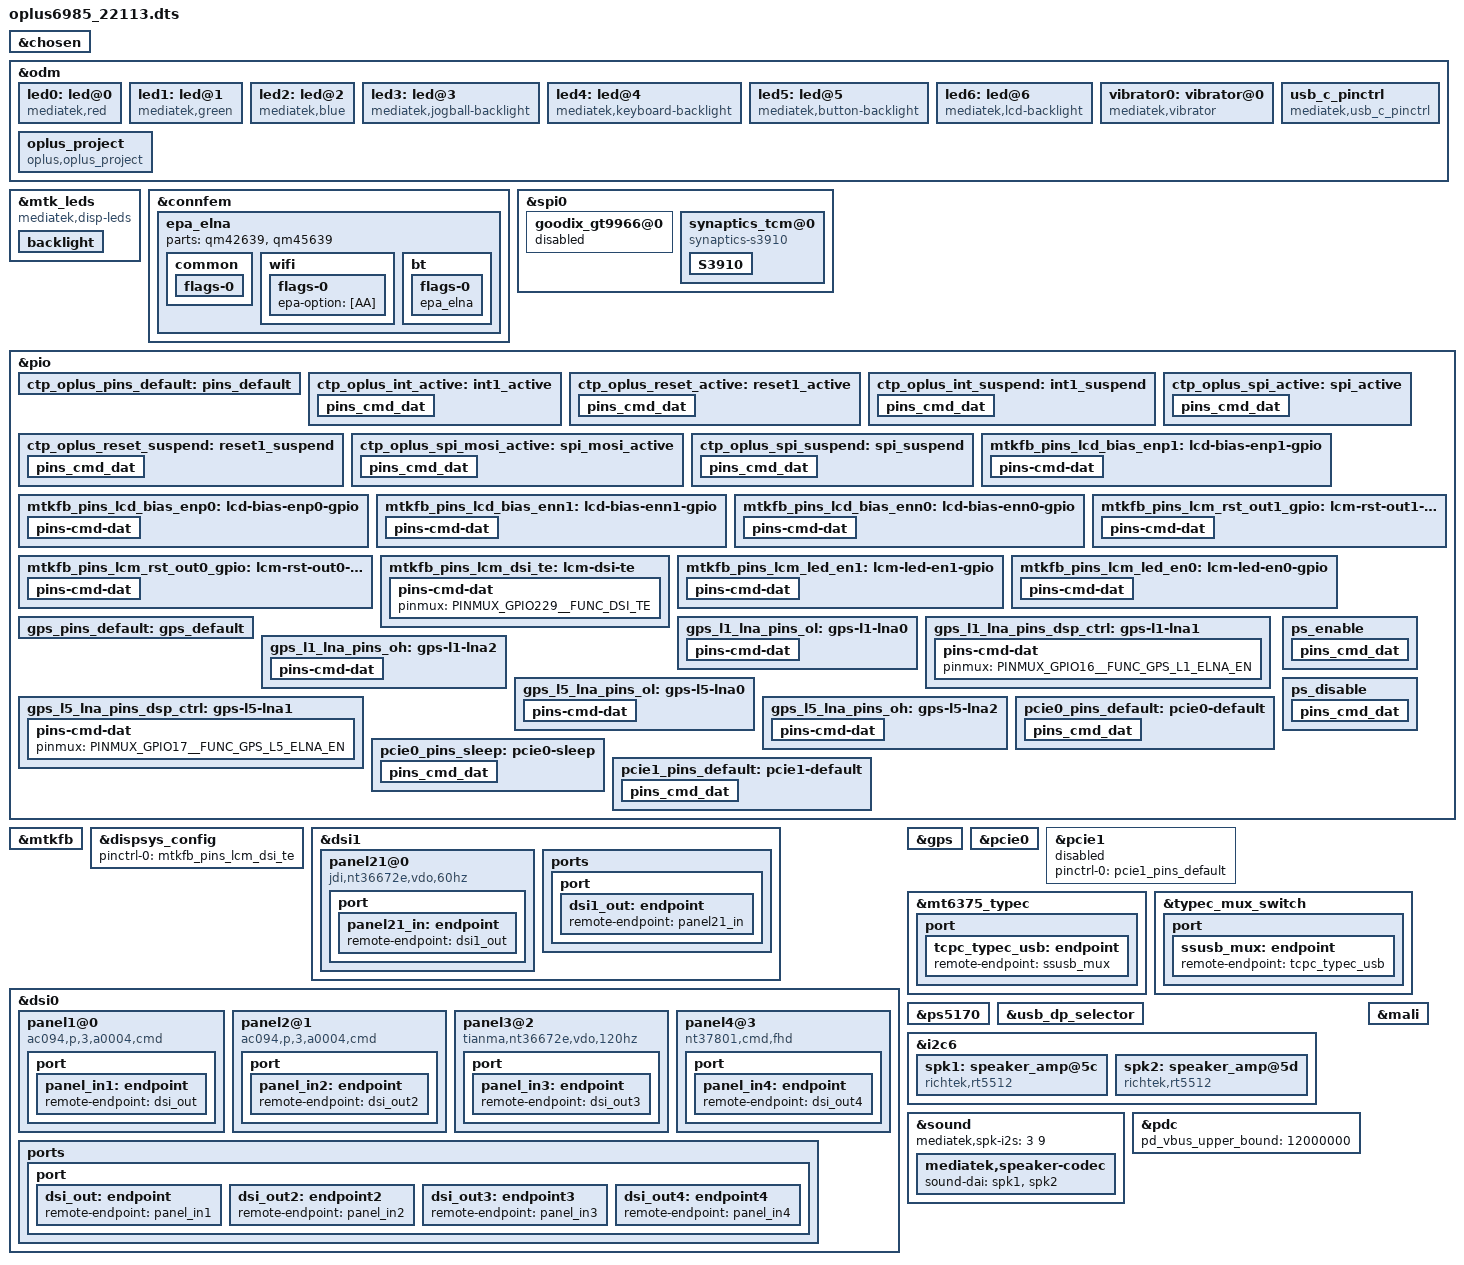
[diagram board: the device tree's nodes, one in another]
// SPDX-License-Identifier: (GPL-2.0 OR MIT)
/*
 * Copyright (C) 2022 MediaTek Inc.
 */
/dts-v1/;
/plugin/;
#include <dt-bindings/interrupt-controller/arm-gic.h>
#include <dt-bindings/interrupt-controller/irq.h>
#include <dt-bindings/pinctrl/mt6985-pinfunc.h>
#include <dt-bindings/phy/phy.h>

&chosen {
bootargs_ext = "console=tty0 root=/dev/ram vmalloc=400M \
loglevel=8 \
androidboot.hardware=mt6985 \
8250.nr_uarts=4 \
initcall_debug=1";
};

/** #ifdef OPLUS_DISPLAY_FEATURE **/
&odm {
	led0:led@0 {
		compatible = "mediatek,red";
		led_mode = <0>;
		data = <1>;
		pwm_config = <0 0 0 0 0>;
	};
	led1:led@1 {
		compatible = "mediatek,green";
		led_mode = <0>;
		data = <1>;
		pwm_config = <0 0 0 0 0>;
	};
	led2:led@2 {
		compatible = "mediatek,blue";
		led_mode = <0>;
		data = <1>;
		pwm_config = <0 0 0 0 0>;
	};
	led3:led@3 {
		compatible = "mediatek,jogball-backlight";
		led_mode = <0>;
		data = <1>;
		pwm_config = <0 0 0 0 0>;
	};
	led4:led@4 {
		compatible = "mediatek,keyboard-backlight";
		led_mode = <0>;
		data = <1>;
		pwm_config = <0 0 0 0 0>;
	};
	led5:led@5 {
		compatible = "mediatek,button-backlight";
		led_mode = <0>;
		data = <1>;
		pwm_config = <0 0 0 0 0>;
	};
	led6:led@6 {
		compatible = "mediatek,lcd-backlight";
		led_mode = <4>;
		data = <1>;
		pwm_config = <0 1 0 0 0>;
	};
	vibrator0:vibrator@0 {
		compatible = "mediatek,vibrator";
		vib_timer = <25>;
		vib_limit = <9>;
		vib_vol= <9>;
	};

	usb_c_pinctrl:usb_c_pinctrl {
		compatible = "mediatek,usb_c_pinctrl";
	};
};

&mtk_leds {
		compatible = "mediatek,disp-leds";
		backlight {
			label = "lcd-backlight";
			led_mode = <4>;
			min-brightness = <1>;
			max-brightness = <4095>;
			max-hw-brightness = <4095>;
			led-bits = <13>;
			trans-bits = <13>;
			default-state = "on";
	};
};
/** #endif OPLUS_DISPLAY_FEATURE **/

&connfem {
	/* Support Wifi & BT ePA/eLNA FEM on customer load */
	epa_elna {
		parts = <&qm42639 &qm45639>;

		common {
			flags-0 {
				rx-mode = [81];
				fe-ant-cnt = [82];
				fe-main-bt-share-lp2g = [81];
				fe-conn-spdt = [8F];
				fe-reserved = [82];
			};
		};

		wifi {
			flags-0 {
				epa-option = [AA];
				/* open-loop; */
			};
		};

		bt {
			flags-0 {
				/* choose one of: epa_elna/epa/elna/bypass */
				epa_elna;
			};
		};
	};
};

&spi0 {
	status = "okay";
	#address-cells = <1>;
	#size-cells = <0>;
 
	goodix_gt9966@0 {
		status = "disabled";
	}; 

	synaptics_tcm@0{
		compatible = "synaptics-s3910";
		reg = <0x0>;
		chip-name = "S3910";
		status = "okay";
		spi-max-frequency = <15000000>;
		/* Interrupt && Irq-gpio */
		interrupt-parent = <&pio>;
		interrupts = <8 0x2008>;

		/* Power Config */
		/* enable2v8_gpio  = <&pio 164 0x1>; */
		vdd_2v8-supply = <&mt6373_vtp>;
		vdd_2v8_volt = <3000000>;
		//vcc_1v8-supply  = <&mt6373_vmc>; 
		//vcc_1v8_volt = <1800000>;

		/* Other HW Resource */

		irq-gpio = <&pio 8 0x2008>;
		reset-gpio = <&pio 67 0x1>;
		//cs-gpio = <&pio 110 0x00>;

		pinctrl-names = "default",  "oplus_int_active",
		"oplus_reset_active", "oplus_int_suspend",
		"oplus_reset_suspend", "oplus_spi_active",
		"oplus_spi_suspend";
		pinctrl-0 = <&ctp_oplus_pins_default>;
		pinctrl-1 = <&ctp_oplus_int_active>;
		pinctrl-2 = <&ctp_oplus_reset_active>;
		pinctrl-3 = <&ctp_oplus_int_suspend>;
		pinctrl-4 = <&ctp_oplus_reset_suspend>;
		pinctrl-5 = <&ctp_oplus_spi_active>, <&ctp_oplus_spi_mosi_active>;
		pinctrl-6 = <&ctp_oplus_spi_suspend>;

		touchpanel,max-num-support = <10>;
		touchpanel,tx-rx-num = <16 36>;
		touchpanel,panel-coords = <12400 27720>;
		touchpanel,display-coords = <1240 2772>;
		touchpanel,touchmajor-limit = <128 216>;
		touchpanel,elimination-range = <20 200 200>;
		touchpanel,int-mode = <1>; /*0: interrupt and disable, 1:interrupt and not disable*/
		touchpanel,smooth-level = <0 1 2 4 7 9>;
		touchpanel,smooth-level-charging = <0 2 4 7 8 9>;
		touchpanel,sensitive-level = <0 70 55 40 25 10>;
		touchpanel,single-optimized-time = <8>;
		touchpanel,high-frame-rate-time = <60>;

		vid_len = <2>;
		panel_type = <7 7 7>; /*type:7 TIANMA*/
		platform_support_project = <21135 22113>;
		platform_support_project_dir = <21135 22113>;
		platform_support_project_commandline = "default_commandline", "oplus21135_tm_nt37705_fhd_dsi_cmd_lcm_drv", "oplus21121_boe_nt37701a_fhd_dsi_cmd_lcm_drv";

		prevention,curved_screen_V2;
		prevention,grip_disable_level = <6>;
		prevention,updelay_time_ms = <30>;
		prevention,makeup_cnt_weight = <4 1 2 2 2>;
		prevention,large_corner_range = <1380 3400>;
		prevention,large_corner_judge_condition = <500 300 1000 7 7>;
		prevention,trx_reject_condition = <8 7 7>;
		prevention,trx_strict_reject_condition = <8 6 6>;
		prevention,large_judge_time_ms = <500 50 30>;
		prevention,large_exit_condition = <8 8 2>;
		prevention,single_channel_width = <320 320>;
		prevention,normal_tap_condition = <10 350>;
		prevention,long_edge_condition = <179 90 120 80>;
		prevention,long_strict_edge_condition = <160 60>;
		prevention,long_fingerhold_condition = <70 6 4 4>;
		prevention,short_edge_condition = <179 90 120 80>;
		prevention,short_strict_edge_condition = <160 60>;
		prevention,large_strict_exit_condition = <6 6>;
		prevention,top_corner_config = <250 750 1000>;
		prevention,edge_swipe_config = <340 1130>;

		prevention,curved_screen_V4;
		prevention,long_eliminate_point_type = <2 12400 9240 240 27720 300 1>;
		prevention,long_fingerhold_condition2 = <700 2000 0 0>;
		prevention,top_corner_config2 =<3 80 600 1500 0>;
		prevention,hor_long_top_corner_config =<300 2000 0 0>;
		prevention,top_middle_config =<12400 1000 1000 0>;
		prevention,corner_eliminate_point_type =<0 1380 2270 1>;
		prevention,finger_hold_differ_size = <1 0 400 300>;
		prevention,finger_hold_max_rx_exit_distance = <5 350 2300>;
		prevention,max_rx_exit_distance = <1 5 150 350 2000>;
		prevention,dynamic_finger_hold_exit_distance = <1 350 2300 450>;

		/* SW Support Feature Control */
		black_gesture_support;
		sportify_aod_gesture_support;
		pressure_report_support;
		charger_pump_support;
		game_switch_support;
		glove_mode_support;
		smart_gesture_support;
		spi_port_support;
		fw_update_app_support;
		fingerprint_underscreen_support;
		freq_hop_simulate_support;
		report_flow_unlock_support;
		screenoff_fingerprint_info_support;
		irq_need_dev_resume_ok;
		enable_point_auto_change;
		kernel_grip_support;
		//grip_no_driver_support;
		health_monitor_support;
		black_gesture_indep_support;
		snr_read_support;
		exception_upload_support;
		/*
		 *Virtual Key Config:
		 *1:touchpanel,button-type: <virtualkey_type  supportted_button-map>
		 *virtualkey_type:
		 *Type 1: using board_properties
		 *Type 2: using same IC (button zone&& touch zone are seprate)
		 *Type 3: using diffrent IC (button zone&& touch zone are seprate)
		 *Type 4: No need of virtual key process
		 *supportted_button-map:select|menu|home|back
		 *
		 *2:touchpanel,button-map
		 *type (X1,Y1)(X2,Y2)(X3,Y3)(Width_X,Hight_Y)--Only when button-type is 0
		 */
		touchpanel,button-type = <4>;
		touchpanel.button-TRx = <0 0>;

		S3910 {
			switch_report_rate;
			report_rate_default = <60>;
			report_rate_game_value = <0x03>;
			fps_report_rate = <60 2 90 3 120 3>;//1:360Hz 2:125Hz 3:240Hz
			fwupdate_bootloader = <1>;
			normal_config_version = <2>;
			default_gesture_mask = <8191>;
		};
	};

};

/*add for nvwa TP*/
&pio {
	ctp_oplus_pins_default: pins_default {
	};
	ctp_oplus_int_active: int1_active {
		pins_cmd_dat {
			pinmux = <PINMUX_GPIO8__FUNC_GPIO8>;
			bias-disable;
			input-enable;
		};
	};
	ctp_oplus_reset_active: reset1_active {
		pins_cmd_dat {
			pinmux = <PINMUX_GPIO67__FUNC_GPIO67>;
			output-high;
		};
	};
	ctp_oplus_int_suspend: int1_suspend {
		pins_cmd_dat {
			pinmux = <PINMUX_GPIO8__FUNC_GPIO8>;
			output-low;
		};
	};
	ctp_oplus_reset_suspend: reset1_suspend {
		pins_cmd_dat {
			pinmux = <PINMUX_GPIO67__FUNC_GPIO67>;
			output-low;
		};
	};
	ctp_oplus_spi_active: spi_active {
		pins_cmd_dat {
			pinmux = <PINMUX_GPIO151__FUNC_SPI0_CSB>,
				<PINMUX_GPIO152__FUNC_SPI0_MO>,
				<PINMUX_GPIO153__FUNC_SPI0_CLK>;
			bias-disable;
			drive-strength = <4>;
		};
	};
	ctp_oplus_spi_mosi_active: spi_mosi_active {
		pins_cmd_dat {
			pinmux = <PINMUX_GPIO150__FUNC_SPI0_MI>;
			bias-pull-up;
			drive-strength = <4>;
		};
	};
	ctp_oplus_spi_suspend: spi_suspend {
		pins_cmd_dat {
			pinmux = < PINMUX_GPIO150__FUNC_GPIO150>,
				< PINMUX_GPIO151__FUNC_GPIO151>,
				<PINMUX_GPIO152__FUNC_GPIO152>,
				< PINMUX_GPIO153__FUNC_GPIO153>;
			bias-disable;
			output-low;
			drive-strength = <4>;
		};
	};
};

&pio {
	mtkfb_pins_lcd_bias_enp1: lcd-bias-enp1-gpio {
		pins-cmd-dat {
			pinmux = <PINMUX_GPIO222__FUNC_GPIO222>;
			slew-rate = <1>;
			output-high;
		};
	};

	mtkfb_pins_lcd_bias_enp0: lcd-bias-enp0-gpio {
		pins-cmd-dat {
			pinmux = <PINMUX_GPIO222__FUNC_GPIO222>;
			slew-rate = <1>;
			output-low;
		};
	};

	mtkfb_pins_lcd_bias_enn1: lcd-bias-enn1-gpio {
		pins-cmd-dat {
			pinmux = <PINMUX_GPIO222__FUNC_GPIO222>;
			slew-rate = <1>;
			output-high;
		};
	};

	mtkfb_pins_lcd_bias_enn0: lcd-bias-enn0-gpio {
		pins-cmd-dat {
			pinmux = <PINMUX_GPIO222__FUNC_GPIO222>;
			slew-rate = <1>;
			output-low;
		};
	};

	mtkfb_pins_lcm_rst_out1_gpio: lcm-rst-out1-gpio {
		pins-cmd-dat {
			pinmux = <PINMUX_GPIO230__FUNC_GPIO230>;
			slew-rate = <1>;
			output-high;
		};
	};

	mtkfb_pins_lcm_rst_out0_gpio: lcm-rst-out0-gpio {
		pins-cmd-dat {
			pinmux = <PINMUX_GPIO230__FUNC_GPIO230>;
			slew-rate = <1>;
			output-low;
		};
	};
	mtkfb_pins_lcm_dsi_te: lcm-dsi-te {
		pins-cmd-dat {
			pinmux = <PINMUX_GPIO229__FUNC_DSI_TE>;
		};
	};

	mtkfb_pins_lcm_led_en1: lcm-led-en1-gpio {
		pins-cmd-dat {
			pinmux = <PINMUX_GPIO215__FUNC_GPIO215>;
			slew-rate = <1>;
			output-high;
		};
	};

	mtkfb_pins_lcm_led_en0: lcm-led-en0-gpio {
		pins-cmd-dat {
			pinmux = <PINMUX_GPIO215__FUNC_GPIO215>;
			slew-rate = <1>;
			output-low;
		};
	};
};

&mtkfb {
	pinctrl-names = "lcd_bias_enp1_gpio", "lcd_bias_enp0_gpio",
		"lcd_bias_enn1_gpio", "lcd_bias_enn0_gpio",
		"lcm_rst_out1_gpio", "lcm_rst_out0_gpio",
		"mode_te_te", "lcm_led_en1_gpio", "lcm_led_en0_gpio";
	pinctrl-0 = <&mtkfb_pins_lcd_bias_enp1>;
	pinctrl-1 = <&mtkfb_pins_lcd_bias_enp0>;
	pinctrl-2 = <&mtkfb_pins_lcd_bias_enn1>;
	pinctrl-3 = <&mtkfb_pins_lcd_bias_enn0>;
	pinctrl-4 = <&mtkfb_pins_lcm_rst_out1_gpio>;
	pinctrl-5 = <&mtkfb_pins_lcm_rst_out0_gpio>;
	pinctrl-6 = <&mtkfb_pins_lcm_dsi_te>;
	pinctrl-7 = <&mtkfb_pins_lcm_led_en1>;
	pinctrl-8 = <&mtkfb_pins_lcm_led_en0>;

	status = "okay";
};


&mtkfb {
	pinctrl-names = "lcd_bias_enp1_gpio", "lcd_bias_enp0_gpio",
		"lcd_bias_enn1_gpio", "lcd_bias_enn0_gpio",
		"lcm_rst_out1_gpio", "lcm_rst_out0_gpio",
		"mode_te_te", "lcm_led_en1_gpio", "lcm_led_en0_gpio";
	pinctrl-0 = <&mtkfb_pins_lcd_bias_enp1>;
	pinctrl-1 = <&mtkfb_pins_lcd_bias_enp0>;
	pinctrl-2 = <&mtkfb_pins_lcd_bias_enn1>;
	pinctrl-3 = <&mtkfb_pins_lcd_bias_enn0>;
	pinctrl-4 = <&mtkfb_pins_lcm_rst_out1_gpio>;
	pinctrl-5 = <&mtkfb_pins_lcm_rst_out0_gpio>;
	pinctrl-6 = <&mtkfb_pins_lcm_dsi_te>;
	pinctrl-7 = <&mtkfb_pins_lcm_led_en1>;
	pinctrl-8 = <&mtkfb_pins_lcm_led_en0>;

	status = "okay";
};


&dispsys_config {
	pinctrl-names = "mode_te_te";
	pinctrl-0 = <&mtkfb_pins_lcm_dsi_te>;
	status = "okay";
};

&dsi1 {
//	status = "okay";
	#address-cells = <1>;
	#size-cells = <0>;
	panel21@0 {
		compatible = "jdi,nt36672e,vdo,60hz";
		reg = <0>;
		pm-enable-gpios = <&pio 68 0>;
		reset-gpios = <&pio 75 0>;
		gate-ic = <4831>;
		pinctrl-names = "default";
		port {
			panel21_in: endpoint {
				remote-endpoint = <&dsi1_out>;
			};
		};
	};
	ports {
		port {
			dsi1_out: endpoint {
				remote-endpoint = <&panel21_in>;
			};
		};
	};
};

#if 0
&dsi1_te {
	interrupt-parent = <&pio>;
	interrupts = <74 1 74 1>;
	status = "okay";
};
#endif

&dsi0 {
	status = "okay";
	#address-cells = <1>;
	#size-cells = <0>;
	/** #ifdef OPLUS_DISPLAY_FEATURE **/
	panel1@0 {
		compatible = "ac094,p,3,a0004,cmd";
		reg = <0>;
		pm-enable-gpios = <&pio 86 0>;
		reset-gpios = <&pio 230 0>;
		1p8-supply = <&mt6373_vrfio18_aif>;
		3p0-supply = <&mt6373_vmc>;
		pinctrl-names = "default";
		port {
			panel_in1: endpoint {
				remote-endpoint = <&dsi_out>;
			};
		};
	};
	panel2@1 {
		compatible = "ac094,p,3,a0004,cmd";
		reg = <1>;
		pm-enable-gpios = <&pio 86 0>;
		reset-gpios = <&pio 230 0>;
		1p8-supply = <&mt6373_vrfio18_aif>;
		3p0-supply = <&mt6373_vmc>;
		pinctrl-names = "default";
		port {
			panel_in2: endpoint {
				remote-endpoint = <&dsi_out2>;
			};
		};
	};
	/** #endif OPLUS_DISPLAY_FEATURE **/
	panel3@2 {
		compatible = "tianma,nt36672e,vdo,120hz";
		reg = <2>;
		pm-enable-gpios = <&pio 68 0>;
		reset-gpios = <&pio 86 0>;
		gate-ic = <4831>;
		pinctrl-names = "default";
		port {
			panel_in3: endpoint {
				remote-endpoint = <&dsi_out3>;
			};
		};
	};
	panel4@3 {
		compatible = "nt37801,cmd,fhd";
		reg = <3>;
		pm-enable-gpios = <&pio 68 0>;
		reset-gpios = <&pio 86 0>;
		gate-ic = <4831>;
		pinctrl-names = "default";
		port {
			panel_in4: endpoint {
				remote-endpoint = <&dsi_out4>;
			};
		};
	};
	ports {
		port {
			dsi_out: endpoint {
				remote-endpoint = <&panel_in1>;
			};

			dsi_out2: endpoint2 {
				remote-endpoint = <&panel_in2>;
			};

			dsi_out3: endpoint3 {
				remote-endpoint = <&panel_in3>;
			};

			dsi_out4: endpoint4 {
				remote-endpoint = <&panel_in4>;
			};
		};
	};
};

/* GPS GPIO standardization start */
&pio {
	gps_pins_default: gps_default {
	};
	gps_l1_lna_pins_ol: gps-l1-lna0 {
		pins-cmd-dat {
			pinmux = <PINMUX_GPIO16__FUNC_GPIO16>;
			output-low;
		};
	};
	gps_l1_lna_pins_dsp_ctrl: gps-l1-lna1 {
		pins-cmd-dat {
			pinmux = <PINMUX_GPIO16__FUNC_GPS_L1_ELNA_EN>;
		};
	};
	gps_l1_lna_pins_oh: gps-l1-lna2 {
		pins-cmd-dat {
			pinmux = <PINMUX_GPIO16__FUNC_GPIO16>;
			output-high;
		};
	};
	gps_l5_lna_pins_ol: gps-l5-lna0 {
		pins-cmd-dat {
			pinmux = <PINMUX_GPIO17__FUNC_GPIO17>;
			output-low;
		};
	};
	gps_l5_lna_pins_dsp_ctrl: gps-l5-lna1 {
		pins-cmd-dat {
			pinmux = <PINMUX_GPIO17__FUNC_GPS_L5_ELNA_EN>;
		};
	};
	gps_l5_lna_pins_oh: gps-l5-lna2 {
		pins-cmd-dat {
			pinmux = <PINMUX_GPIO17__FUNC_GPIO17>;
			output-high;
		};
	};
};

&gps {
	pinctrl-names = "default",
		"gps_l1_lna_disable",
		"gps_l1_lna_dsp_ctrl",
		"gps_l1_lna_enable",
		"gps_l5_lna_disable",
		"gps_l5_lna_dsp_ctrl",
		"gps_l5_lna_enable";
	pinctrl-0 = <&gps_pins_default>;
	pinctrl-1 = <&gps_l1_lna_pins_ol>;
	pinctrl-2 = <&gps_l1_lna_pins_dsp_ctrl>;
	pinctrl-3 = <&gps_l1_lna_pins_oh>;
	pinctrl-4 = <&gps_l5_lna_pins_ol>;
	pinctrl-5 = <&gps_l5_lna_pins_dsp_ctrl>;
	pinctrl-6 = <&gps_l5_lna_pins_oh>;
	status = "okay";
};
/* GPS GPIO standardization end */

/* PCIe pinmux start */
&pcie0 {
	pinctrl-names = "default", "sleep";
	pinctrl-0 = <&pcie0_pins_default>;
	pinctrl-1 = <&pcie0_pins_sleep>;
	status = "okay";
};

&pcie1 {
	pinctrl-names = "default";
	pinctrl-0 = <&pcie1_pins_default>;
	status = "disabled";
};

&pio {
	pcie0_pins_default: pcie0-default {
		pins_cmd_dat {
			/* PINMUX_GPIO231__FUNC_PCIE_WAKEN for Falcon */
			pinmux = <PINMUX_GPIO143__FUNC_PCIE_PERSTN>,
				 <PINMUX_GPIO145__FUNC_PCIE_CLKREQN>;
			bias-pull-up;
		};
	};

	pcie0_pins_sleep: pcie0-sleep {
		pins_cmd_dat {
			/* PINMUX_GPIO231__FUNC_GPIO231 for Falcon */
			pinmux = <PINMUX_GPIO143__FUNC_GPIO143>,
				 <PINMUX_GPIO145__FUNC_GPIO145>;
			bias-pull-down;
			input-enable;
		};
	};

	pcie1_pins_default: pcie1-default {
		pins_cmd_dat {
			pinmux = <PINMUX_GPIO0__FUNC_PCIE_PERSTN_P1>,
				 <PINMUX_GPIO1__FUNC_PCIE_WAKEN_P1>,
				 <PINMUX_GPIO2__FUNC_PCIE_CLKREQN_P1>;
			bias-pull-up;
		};
	};
};
/* PCIe pinmux end */

/* usb typec mux start */
&pio {

	ps_enable: ps_enable {
		pins_cmd_dat {
			pinmux = <PINMUX_GPIO204__FUNC_GPIO204>;
			output-high;
		};
	};

	ps_disable: ps_disable {
		pins_cmd_dat {
			pinmux = <PINMUX_GPIO204__FUNC_GPIO204>;
			output-low;
		};
	};

};

&mt6375_typec {
	port {
		tcpc_typec_usb: endpoint {
			remote-endpoint = <&ssusb_mux>;
		};
	};
};

&typec_mux_switch {
	orientation-switch;
	mode-switch;
	accessory;
	port {
		ssusb_mux: endpoint {
			remote-endpoint = <&tcpc_typec_usb>;
		};
	};
};

&ps5170 {
	pinctrl-names = "enable", "disable";
	pinctrl-0 = <&ps_enable>;
	pinctrl-1 = <&ps_disable>;
	status = "okay";
};

&usb_dp_selector {
	status = "okay";
};
/* usb typec mux end */

#include "mediatek/cust_mt6985_touch_1080x2400.dtsi"

&i2c6 {
	spk1: speaker_amp@5c {
		compatible = "richtek,rt5512";
		#sound-dai-cells = <0>;
		reg = <0x5c>;
		status = "okay";
		sound-name-prefix = "Left";
	};

	spk2: speaker_amp@5d {
		compatible = "richtek,rt5512";
		#sound-dai-cells = <0>;
		reg = <0x5d>;
		status = "okay";
		sound-name-prefix = "Right";
	};
};

&sound {
	mediatek,spk-i2s = <3 9>;
	mediatek,speaker-codec {
		sound-dai = <&spk1>, <&spk2>;
	};
};

&pdc {
	pd_vbus_upper_bound = <12000000>;
};

&mali {
	sleep-mode-enable = <1>;
	adaptive-power-policy = <1>;
	default-glb-pwroff-timeout-us = <300>;
};

&odm {
/*OPLUS_FEATURE_OEM_OCDT oppo project start */
	oplus_project:oplus_project {
		compatible = "oplus,oplus_project";
	};
};

#include "mediatek/cust_k6985_connfem.dtsi"
#include "mediatek/cust_mt6985_camera_v4l2.dtsi"
#include <oplus6985_22113/cust.dtsi>
/*End of this file, DO NOT ADD ANYTHING HERE*/

